# VPAC0_PAR_VPAC_VISS0_S_VBUSP_VPAC_VISS_LSE_CFG_VP register map
Vendor: Texas Instruments
Peripheral module from a debugger description file (folder J7ES).
Registers are 32-bit, access per field, reset 0x0 unless marked. A register's access mark holds for its fields unless they carry their own. Offsets are as the file gives them; lines under a group give offsets from that group; [hi:lo] are bit positions; {n}, {i} and the like mark numbered series; 'fields as' and 'values as' point back to an identical list; <NAME> marks a mode.

## VPAC0_PAR_VPAC_VISS0_S_VBUSP_VPAC_VISS_LSE_CFG_VP
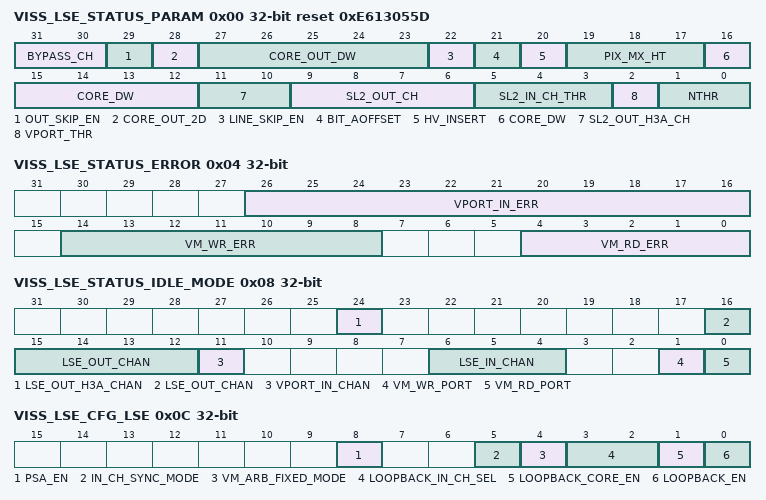
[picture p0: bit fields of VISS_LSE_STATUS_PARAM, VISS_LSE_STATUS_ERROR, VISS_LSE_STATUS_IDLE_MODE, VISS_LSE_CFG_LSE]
0x00 VISS_LSE_STATUS_PARAM ro reset 0xE613055D — The register returns the LSE compile configuration parameters.
  [31:30] BYPASS_CH — Number of available input channel selection for loopback mode
  [29] OUT_SKIP_EN — Output Auto-Skip Enable
  [28] CORE_OUT_2D — 1D or 2D output addressing mode(2D if 1)
  [27:23] CORE_OUT_DW — Core Output Channel Data Width
  [22] LINE_SKIP_EN — Source Line Inc by 2 Supported (if 1)
  [21] BIT_AOFFSET — Source nibble offset address Supported (if 1)
  [20] HV_INSERT — H/VBLANK Insertion Supported (if 1)
  [19:17] PIX_MX_HT — Core_Input Pixel Matrix Height
  [16:12] CORE_DW — Core Input Data Bus Width
  [11:10] SL2_OUT_H3A_CH — Number of SL2 H3A Output Channels
  [9:6] SL2_OUT_CH — Number of SL2 Output Channels
  [5:3] SL2_IN_CH_THR — Number of Input Channels per thread
  [2] VPORT_THR — Number of VPORT input enabled
  [1:0] NTHR — Number of threads supported
0x04 VISS_LSE_STATUS_ERROR access not given — The register returns the LSE error status.
  [26:16] VPORT_IN_ERR — VPORT_CAL Input Error Status Protocol Errors [26] VS without HS [25] VE without HE [24] VS-VS (missing VE) Error [23] HS-HS (missing HE) Error [22] HE-HE (missing HS) Error [21] VE-VE (missing VS) Error Frame Size Errors [20] Frame Skipped during Error Handling [19] Long Frame detected [18] Short Frame detected [17] Long Line detected [16] Short Line Detected (access RW1C)
  [14:8] VM_WR_ERR — VBUSM I/F Last Write Error Status (access RW1C)
  [4:0] VM_RD_ERR — VBUSM I/F Last Read Error Status (access RW1C)
0x08 VISS_LSE_STATUS_IDLE_MODE ro — The register returns IDLE status of LSE VBUSM port and in/output channels - 0: IDLE 1: ACTIVE
  [24] LSE_OUT_H3A_CHAN — Output H3A Channel Status
  [16:12] LSE_OUT_CHAN — Output Channel
  [11] VPORT_IN_CHAN — CAL I/F Vport Input Cahnnel Status
  [6:4] LSE_IN_CHAN — Input Channel
  [1] VM_WR_PORT — SL2 vbusm I/F Write Port Status
  [0] VM_RD_PORT — SL2 vbusm I/F Read Port Status
0x0C VISS_LSE_CFG_LSE rw — The register configures the LSE general hardware modes.
  [8] PSA_EN — Test mode Output Channel Signature Generation Enable
  [5] IN_CH_SYNC_MODE — Input Channel Transfer Sync Mode (applicable only for VISS)
  [4] VM_ARB_FIXED_MODE — VBUSM Arbitration Fixed Mode select
  [3:2] LOOPBACK_IN_CH_SEL — Loopback Input Channel Select (applicable only for VISS)
  [1] LOOPBACK_CORE_EN — Functional path (data to HWA core) enable during loopback mode
  [0] LOOPBACK_EN — LSE loopback mode enable
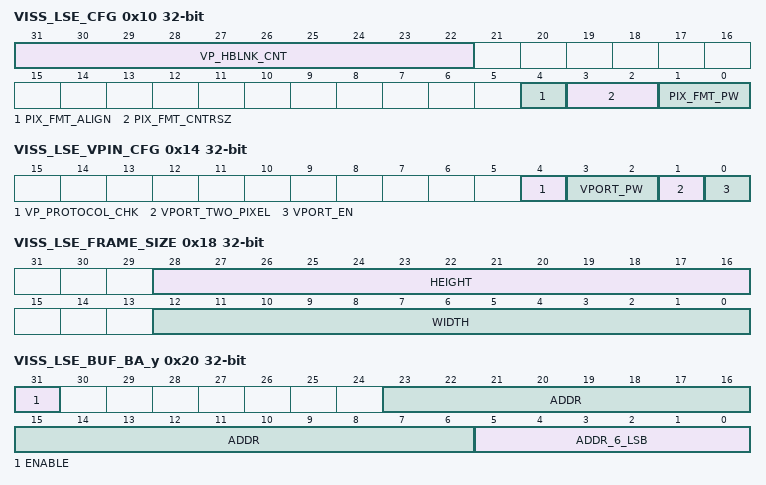
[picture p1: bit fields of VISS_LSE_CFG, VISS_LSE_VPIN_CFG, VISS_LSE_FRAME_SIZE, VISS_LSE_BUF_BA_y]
0x10 VISS_LSE_CFG rw — The SRC_CFG register configures the input channels for the processing thread
  [31:22] VP_HBLNK_CNT — Number of HBlank Pixels to insert between active lines for internal vport interface to core.
  [4] PIX_FMT_ALIGN — Input Pixel Container Alignment
  [3:2] PIX_FMT_CNTRSZ — Input Pixel Container Size Sel
  [1:0] PIX_FMT_PW — Input Pixel Width Sel
0x14 VISS_LSE_VPIN_CFG rw — The SRC_VPIN_CFG register configures the VPORT input channel for the processing thread
  [4] VP_PROTOCOL_CHK — Vport Input Data Protocol Check Enable
  [3:2] VPORT_PW — Vport Pixel Data Width Sel
  [1] VPORT_TWO_PIXEL — Number of pixels per vport cycles
  [0] VPORT_EN
0x18 VISS_LSE_FRAME_SIZE rw — The SRC_FRAME_SIZE register configures the frame size of all input buffers for the processing thread .
  [28:16] HEIGHT — SL
  [12:0] WIDTH — SL
0x20 VISS_LSE_BUF_BA_y — The SRC_BUF_BA[b] register configures the base address of the SL2 source buffer [b] for the processing thread . Offset = 00080420h + (y * 4h); where y = 0h to 2h
  [31] ENABLE rw — Input Buffer Enable
  [23:6] ADDR rw — Base Address
  [5:0] ADDR_6_LSB ro — Base Address
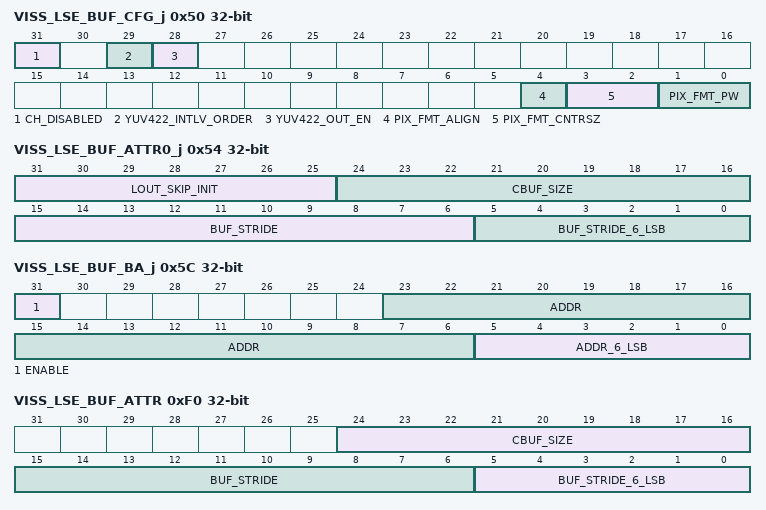
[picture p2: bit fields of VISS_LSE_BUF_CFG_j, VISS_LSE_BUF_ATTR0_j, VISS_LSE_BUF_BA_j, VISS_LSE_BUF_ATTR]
0x50 VISS_LSE_BUF_CFG_j — The DST_BUF_CFG register configures the output buffer channel . Offset = 00080450h + (j * 10h); where j = 0h to 4h
  [31] CH_DISABLED ro — Channel Disable Status (read-only)
  [29] YUV422_INTLV_ORDER rw — YUV422 Interleaving Order Selection
  [28] YUV422_OUT_EN rw — YUV422 Interleaved Output Merge Enable
  [4] PIX_FMT_ALIGN rw — Output Pixel Container Alignment
  [3:2] PIX_FMT_CNTRSZ rw — Output Pixel Container Size Sel
  [1:0] PIX_FMT_PW rw — Output Pixel Width Sel
0x54 VISS_LSE_BUF_ATTR0_j — The DST_BUF_ATTR0 register configures the attributes of the output SL2 buffer . Offset = 00080454h + (j * 10h); where j = 0h to 4h
  [31:25] LOUT_SKIP_INIT rw — Line Out Initial Skip Count - The number of initial HTS tstart/tdone cycles with no output from the core on this output channel.
  [24:16] CBUF_SIZE rw — SL2 Circular Buffer Size (number of line buffers)
  [15:6] BUF_STRIDE rw — Buffer Stride Size
  [5:0] BUF_STRIDE_6_LSB ro — Buffer Stride Size
0x5C VISS_LSE_BUF_BA_j — The DST_BUF_BA register configures the base address of the output SL2 circular buffer . Offset = 0008045Ch + (j * 10h); where j = 0h to 4h
  [31] ENABLE rw — Output Channel Enable
  [23:6] ADDR rw — Base Address
  [5:0] ADDR_6_LSB ro — Base Address
0xF0 VISS_LSE_BUF_ATTR — The SRC_BUF_ATTR register configures the common attributes of all SL2 source buffers for the processing thread .
  [24:16] CBUF_SIZE rw — SL2 Circular Buffer Size (number of line buffers)
  [15:6] BUF_STRIDE rw — Buffer Stride Size
  [5:0] BUF_STRIDE_6_LSB ro — Buffer Stride Size
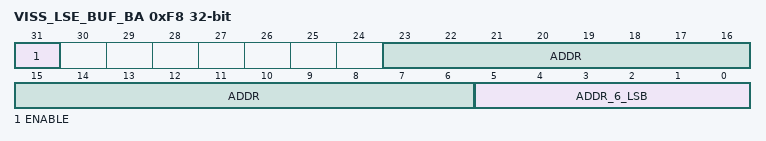
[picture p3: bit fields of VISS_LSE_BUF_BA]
0xF8 VISS_LSE_BUF_BA — The H3A_BUF_BA register configures the base address of the H3A output SL2 circular buffer.
  [31] ENABLE rw — Output H3A Buffer Enable
  [23:6] ADDR rw — Base Address
  [5:0] ADDR_6_LSB ro — Base Address
0x140 VISS_LSE_PSA_SIGNATURE_y ro — The PSA_SIGNATURE register returns the captured PSA signature value of the last frame data of output channel [a]. Offset = 00080540h + (y * 4h); where y = 0h to 5h
  [31:0] VALUE — 32-bit CRC signature value
0x1E0 VISS_LSE_DBG_y ro — The DBG register returns the current status of internal FSM - TI internal use only. Offset = 000805E0h + (y * 4h); where y = 0h to 4h
  [31:0] STATUS — Debug status
